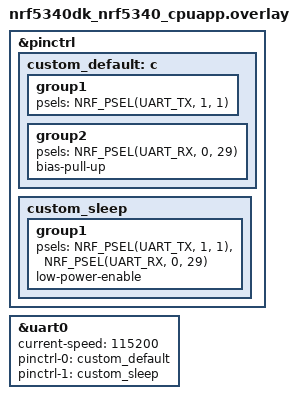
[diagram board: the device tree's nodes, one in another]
/*
 * Copyright (c) 2023 Culvert, Inc
 *
 * SPDX-License-Identifier: LicenseRef-BSD-5-Clause-Nordic
 *
 * This is required to get MCUBoot console working on D1
 */

&pinctrl {
	custom_default: c {
		group1 {
			psels = <NRF_PSEL(UART_TX, 1, 1)>;
		};
		group2 {
			psels = <NRF_PSEL(UART_RX, 0, 29)>;
			bias-pull-up;
		};
	};

	custom_sleep: custom_sleep {
		group1 {
			psels = <NRF_PSEL(UART_TX, 1, 1)>,
				<NRF_PSEL(UART_RX, 0, 29)>;
			low-power-enable;
		};
	};
};

&uart0 {
	status = "okay";
	current-speed = <115200>;
	pinctrl-0 = <&custom_default>;
	pinctrl-1 = <&custom_sleep>;
	pinctrl-names = "default", "sleep";
};
